# MU3E_EMULATOR_MUTRIG register map
Vendor: Mu3e; Series: MU3E_FPGA_IP; File version: 26.1.13.0425
MuTRiG 3 digital-output emulator CSR aperture.
Registers are 32-bit, read-write, reset 0x1 unless marked. A register's access mark holds for its fields unless they carry their own. Offsets are from the block's base; lines under a group give offsets from that group; [hi:lo] are bit positions; {n}, {i} and the like mark numbered series; 'fields as' and 'values as' point back to an identical list; <NAME> marks a mode.

## Memory map
0x00000000 EMULATOR_MUTRIG_CSR size 0x40 — Relative 16-word configuration and status window for one emulator instance.

## EMULATOR_MUTRIG_CSR — Relative 16-word configuration and status window for one emulator instance.
Base 0x00000000
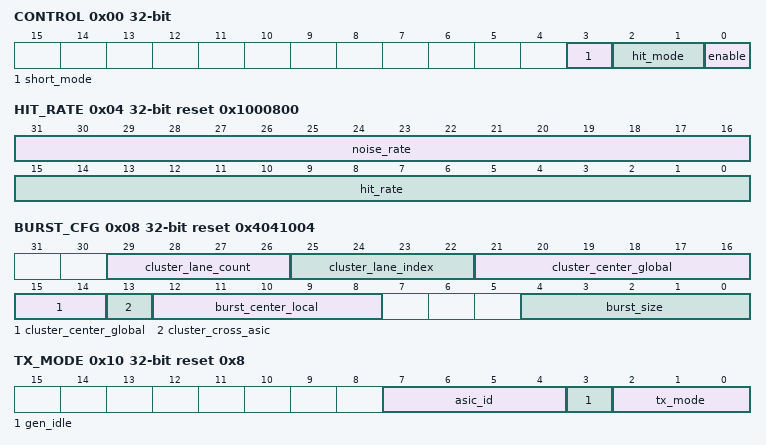
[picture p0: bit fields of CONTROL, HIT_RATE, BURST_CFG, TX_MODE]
0x00 CONTROL — Main emulator enable and hit-generation mode.
  [3] short_mode — 1 selects short frame interval; 0 selects long frame interval.
  [2:1] hit_mode — 0=legacy folded Poisson, 1=burst/injected cluster replay, 2=folded per-channel IID Poisson, 3=folded per-channel periodic.
  [0] enable — Enable hit generation/output.
0x04 HIT_RATE reset 0x1000800 — Fixed-point hit and noise rates.
  [31:16] noise_rate — 8.8 fixed-point noise-rate control.
  [15:0] hit_rate — 8.8 fixed-point hit-rate control.
0x08 BURST_CFG reset 0x4041004 — Burst and multi-ASIC cluster configuration.
  [29:26] cluster_lane_count — Number of lanes in the shared cluster domain.
  [25:22] cluster_lane_index — Lane index inside the shared cluster domain.
  [21:14] cluster_center_global — Global cluster center when cross-ASIC mode is enabled.
  [13] cluster_cross_asic — Enable shared global cluster across ASIC lanes.
  [12:8] burst_center_local — Local 32-channel burst center.
  [4:0] burst_size — Local burst size.
0x0C PRNG_SEED reset 0xDEADBEEF — Hit generator PRNG seed.
  [31:0] seed — 32-bit PRNG seed.
0x10 TX_MODE reset 0x8 — Frame output mode and ASIC channel tag.
  [7:4] asic_id — ASIC ID/channel tag, clamped to 0..7 by RTL.
  [3] gen_idle — Generate idle words when enabled.
  [2:0] tx_mode — Frame assembler TX mode.
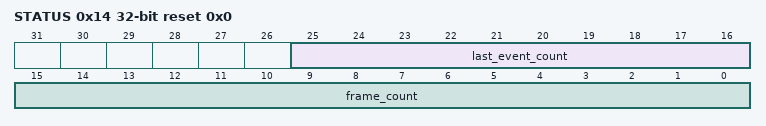
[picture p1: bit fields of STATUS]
0x14 STATUS ro reset 0x0 — Frame and event counters captured at frame start.
  [25:16] last_event_count — Last event count captured at frame start.
  [15:0] frame_count — Frame-start counter.
0x18 INJECT_MASK reset 0xFFFFFFFF — Masked injection channel participation mask.
  [31:0] channel_mask — Bit N enables channel N for masked injection triggers.
